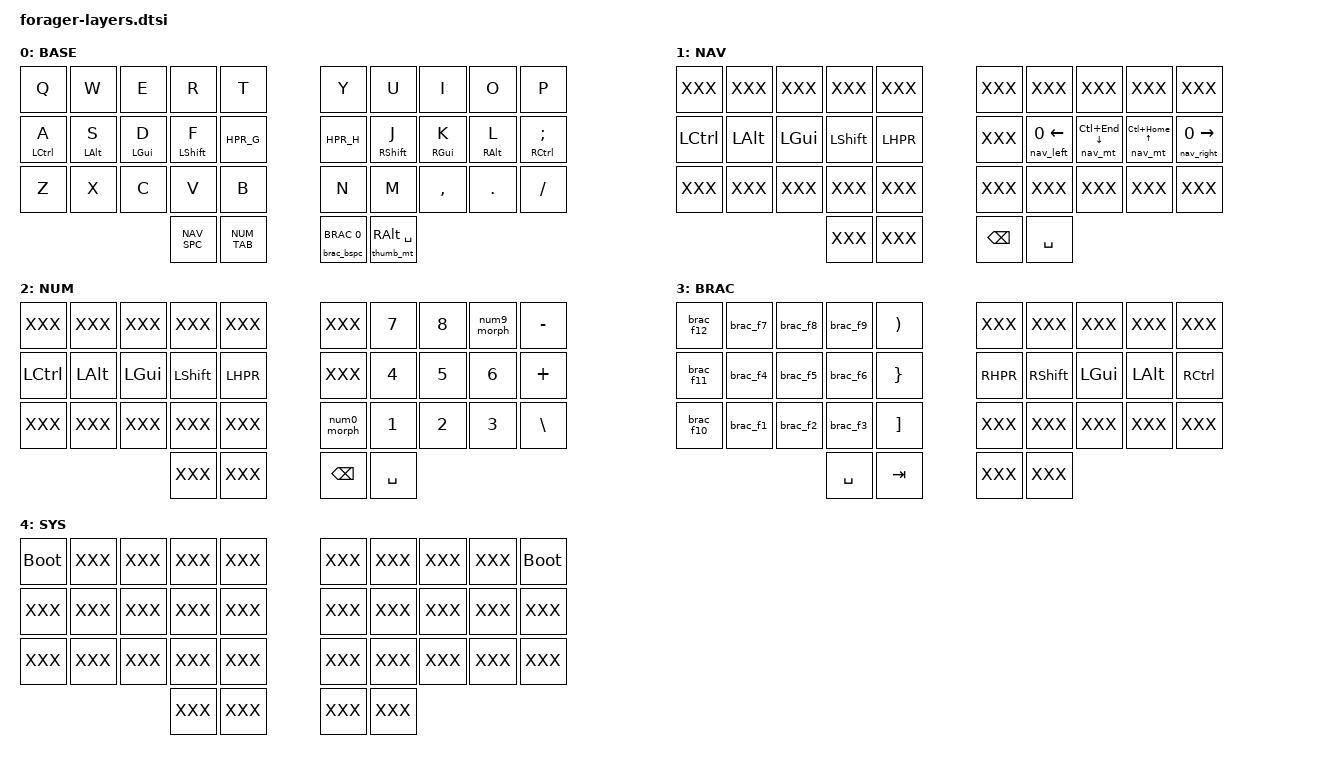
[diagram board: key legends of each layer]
/ {
    keymap {
        compatible = "zmk,keymap";

        base_layer {
            label = "BASE";
            bindings = <
//                       ╭─────────────┬─────────────┬─────────────┬─────────────┬─────────────╮   ╭─────────────┬─────────────┬─────────────┬─────────────┬─────────────╮
                           &kp Q         &kp W         &kp E         &kp R         &kp T             &kp Y         &kp U         &kp I         &kp O         &kp P
//                       ├─────────────┼─────────────┼─────────────┼─────────────┼─────────────┤   ├─────────────┼─────────────┼─────────────┼─────────────┼─────────────┤
                           &hml LCTRL A  &hml LALT S   &hml LGUI D   &hml LSHFT F  HPR_G             HPR_H         &hmr RSHFT J  &hmr RGUI  K  &hmr RALT L   &hmr RCTRL SEMI
//                       ├─────────────┼─────────────┼─────────────┼─────────────┼─────────────┤   ├─────────────┼─────────────┼─────────────┼─────────────┼─────────────┤
                           &kp Z         &kp X         &kp C         &kp V         &kp B             &kp N         &kp M         &kp COMMA     &kp DOT       &kp FSLH
//                       ╰─────────────┴─────────────┼─────────────┼─────────────┼─────────────┤   ├─────────────┼─────────────┼─────────────┼─────────────┴─────────────╯
                                                                     NAV_SPC       NUM_TAB           &brac_bspc BRAC 0  &thumb_mt RALT SPACE
//                                                                 ╰─────────────┴─────────────╯   ╰─────────────┴─────────────╯
            >;
        };

        nav_layer {
            label = "NAV";
            bindings = <
//                       ╭─────────────┬─────────────┬─────────────┬─────────────┬─────────────╮   ╭─────────────┬─────────────┬─────────────┬─────────────┬─────────────╮
                           XXX           XXX           XXX           XXX           XXX               XXX           XXX           XXX           XXX           XXX
//                       ├─────────────┼─────────────┼─────────────┼─────────────┼─────────────┤   ├─────────────┼─────────────┼─────────────┼─────────────┼─────────────┤
                           &kp LCTRL     &kp LALT      &kp LGUI      &kp LSHFT     LHPR              XXX           &nav_left 0 LEFT  &nav_mt LC(END) DOWN  &nav_mt LC(HOME) UP  &nav_right 0 RIGHT
//                       ├─────────────┼─────────────┼─────────────┼─────────────┼─────────────┤   ├─────────────┼─────────────┼─────────────┼─────────────┼─────────────┤
                           XXX           XXX           XXX           XXX           XXX               XXX           XXX           XXX           XXX           XXX
//                       ╰─────────────┴─────────────┼─────────────┼─────────────┼─────────────┤   ├─────────────┼─────────────┼─────────────┼─────────────┴─────────────╯
                                                                     XXX           XXX               &kp BSPC      &kp SPACE
//                                                                 ╰─────────────┴─────────────╯   ╰─────────────┴─────────────╯
            >;
        };

        num_layer {
            label = "NUM";
            bindings = <
//                       ╭─────────────┬─────────────┬─────────────┬─────────────┬─────────────╮   ╭─────────────┬─────────────┬─────────────┬─────────────┬─────────────╮
                           XXX           XXX           XXX           XXX           XXX               XXX           &kp N7        &kp N8        &num9_morph   &kp MINUS
//                       ├─────────────┼─────────────┼─────────────┼─────────────┼─────────────┤   ├─────────────┼─────────────┼─────────────┼─────────────┼─────────────┤
                           &kp LCTRL      &kp LALT      &kp LGUI     &kp LSHFT     LHPR              XXX           &kp N4        &kp N5        &kp N6        &kp PLUS
//                       ├─────────────┼─────────────┼─────────────┼─────────────┼─────────────┤   ├─────────────┼─────────────┼─────────────┼─────────────┼─────────────┤
                           XXX           XXX           XXX           XXX           XXX               &num0_morph   &kp N1        &kp N2        &kp N3        &kp BSLH
//                       ╰─────────────┴─────────────┼─────────────┼─────────────┼─────────────┤   ├─────────────┼─────────────┼─────────────┼─────────────┴─────────────╯
                                                                     XXX           XXX               &kp BSPC      &kp SPACE
//                                                                 ╰─────────────┴─────────────╯   ╰─────────────┴─────────────╯
            >;
        };

        brac_layer {
            label = "BRAC";
            bindings = <
//                       ╭─────────────┬─────────────┬─────────────┬─────────────┬─────────────╮   ╭─────────────┬─────────────┬─────────────┬─────────────┬─────────────╮
                           &brac_f12     &brac_f7      &brac_f8      &brac_f9      &kp RPAR          XXX           XXX           XXX           XXX           XXX
//                       ├─────────────┼─────────────┼─────────────┼─────────────┼─────────────┤   ├─────────────┼─────────────┼─────────────┼─────────────┼─────────────┤
                           &brac_f11     &brac_f4      &brac_f5      &brac_f6      &kp RBRC          RHPR          &kp RSHFT     &kp LGUI      &kp LALT      &kp RCTRL
//                       ├─────────────┼─────────────┼─────────────┼─────────────┼─────────────┤   ├─────────────┼─────────────┼─────────────┼─────────────┼─────────────┤
                           &brac_f10     &brac_f1      &brac_f2      &brac_f3      &kp RBKT          XXX           XXX           XXX           XXX           XXX
//                       ╰─────────────┴─────────────┼─────────────┼─────────────┼─────────────┤   ├─────────────┼─────────────┼─────────────┼─────────────┴─────────────╯
                                                                     &kp SPACE     &kp TAB           XXX           XXX
//                                                                 ╰─────────────┴─────────────╯   ╰─────────────┴─────────────╯
            >;
        };

        // Reached by holding both layer thumbs (NUM + BRAC), see
        // conditional_layers below - deliberately hard to hit by accident.
        // &bootloader runs on the half the key is on: Q puts the left half
        // into UF2 flashing mode, P the right one. For the dongle see
        // combo_dongle_bootloader (B + N).
        sys_layer {
            label = "SYS";
            bindings = <
//                       ╭─────────────┬─────────────┬─────────────┬─────────────┬─────────────╮   ╭─────────────┬─────────────┬─────────────┬─────────────┬─────────────╮
                           &bootloader   XXX           XXX           XXX           XXX               XXX           XXX           XXX           XXX           &bootloader
//                       ├─────────────┼─────────────┼─────────────┼─────────────┼─────────────┤   ├─────────────┼─────────────┼─────────────┼─────────────┼─────────────┤
                           XXX           XXX           XXX           XXX           XXX               XXX           XXX           XXX           XXX           XXX
//                       ├─────────────┼─────────────┼─────────────┼─────────────┼─────────────┤   ├─────────────┼─────────────┼─────────────┼─────────────┼─────────────┤
                           XXX           XXX           XXX           XXX           XXX               XXX           XXX           XXX           XXX           XXX
//                       ╰─────────────┴─────────────┼─────────────┼─────────────┼─────────────┤   ├─────────────┼─────────────┼─────────────┼─────────────┴─────────────╯
                                                                     XXX           XXX               XXX           XXX
//                                                                 ╰─────────────┴─────────────╯   ╰─────────────┴─────────────╯
            >;
        };
    };

    conditional_layers {
        compatible = "zmk,conditional-layers";
        sys_tri_layer {
            if-layers = <NUM BRAC>;
            then-layer = <SYS>;
        };
    };
};
